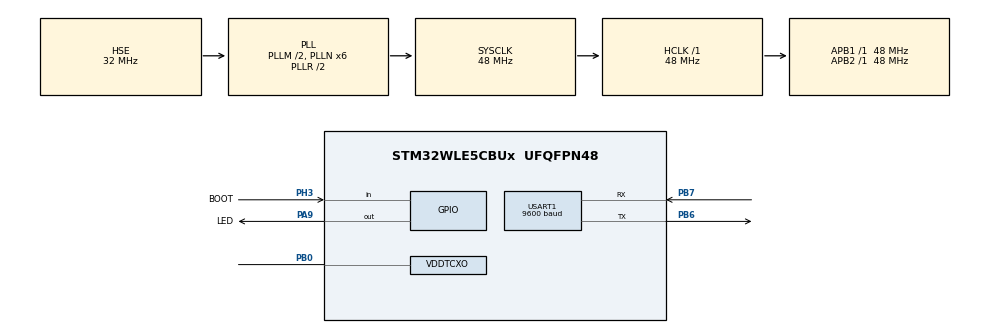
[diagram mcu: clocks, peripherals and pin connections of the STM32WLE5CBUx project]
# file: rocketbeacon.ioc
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ADC.NbrOfConversion=1
ADC.SelectedChannel=ADC_CHANNEL_VBAT
Dma.Request0=USART1_RX
Dma.USART1_RX.0.Direction=DMA_PERIPH_TO_MEMORY
Dma.USART1_RX.0.EventEnable=DISABLE
Dma.USART1_RX.0.Instance=DMA1_Channel1
Dma.USART1_RX.0.MemDataAlignment=DMA_MDATAALIGN_BYTE
Dma.USART1_RX.0.MemInc=DMA_MINC_ENABLE
Dma.USART1_RX.0.Mode=DMA_NORMAL
Dma.USART1_RX.0.PeriphDataAlignment=DMA_PDATAALIGN_BYTE
Dma.USART1_RX.0.PeriphInc=DMA_PINC_DISABLE
Dma.USART1_RX.0.Polarity=HAL_DMAMUX_REQ_GEN_RISING
Dma.USART1_RX.0.Priority=DMA_PRIORITY_MEDIUM
Dma.USART1_RX.0.RequestNumber=1
Dma.USART1_RX.0.SignalID=NONE
Dma.USART1_RX.0.SyncEnable=DISABLE
Dma.USART1_RX.0.SyncPolarity=HAL_DMAMUX_SYNC_NO_EVENT
Dma.USART1_RX.0.SyncRequestNumber=1
Dma.USART1_RX.0.SyncSignalID=NONE
Mcu.Family=STM32WL
Mcu.Name=STM32WLE5CBUx
Mcu.Package=UFQFPN48
NVIC.DMA1_Channel1_IRQn=true\:0\:0\:false\:false\:true\:false\:true\:true
NVIC.PriorityGroup=NVIC_PRIORITYGROUP_4
NVIC.USART1_IRQn=true\:0\:0\:false\:false\:true\:true\:true\:true
OSC_IN.Mode=HSE-TCXO
OSC_IN.Signal=RCC_OSC_IN
PA13.Mode=Serial_Wire
PA13.Signal=DEBUG_JTMS-SWDIO
PA14.Mode=Serial_Wire
PA14.Signal=DEBUG_JTCK-SWCLK
PA9.GPIO_Label=LED
PA9.Signal=GPIO_Output
PB0-VDD_TCXO.Mode=HSE-TCXO
PB0-VDD_TCXO.Signal=VDDTCXO
PB6.Mode=Asynchronous
PB6.Signal=USART1_TX
PB7.Mode=Asynchronous
PB7.Signal=USART1_RX
PH3-BOOT0.GPIO_Label=BOOT
PH3-BOOT0.Signal=GPIO_Input
ProjectManager.HeapSize=0x200
ProjectManager.StackSize=0x400
ProjectManager.TargetToolchain=STM32CubeIDE
RCC.AHB3CLKDivider=RCC_SYSCLK_DIV16
RCC.AHBFreq_Value=48000000
RCC.APB1Freq_Value=48000000
RCC.APB1TimFreq_Value=48000000
RCC.APB2Freq_Value=48000000
RCC.APB2TimFreq_Value=48000000
RCC.APB3Freq_Value=3000000
RCC.CortexFreq_Value=48000000
RCC.HCLKFreq_Value=48000000
RCC.HSE_VALUE=32000000
RCC.HSI_VALUE=16000000
RCC.LSE_VALUE=32768
RCC.PLLM=RCC_PLLM_DIV2
RCC.PLLN=6
RCC.PLLSourceVirtual=RCC_PLLSOURCE_HSE
RCC.SYSCLKFreq_VALUE=48000000
RCC.SYSCLKSource=RCC_SYSCLKSOURCE_PLLCLK
RCC.VCOOutputFreq_Value=96000000
USART1.BaudRate=9600
USART1.VirtualMode-Asynchronous=VM_ASYNC
VP_ADC_Vbat_Input.Mode=IN-Vbat
VP_CRC_VS_CRC.Mode=CRC_Activate
VP_SUBGHZ_VS_SUBGHZ.Mode=SUBGHZ_Activate
VP_TIM16_VS_ClockSourceINT.Mode=Enable_Timer
board=custom

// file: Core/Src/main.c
/* USER CODE BEGIN Header */
/**
  ******************************************************************************
  * @file           : main.c
  * @brief          : Main program body
  ******************************************************************************
  * @attention
  *
  * Copyright (c) 2024 STMicroelectronics.
  * All rights reserved.
  *
  * This software is licensed under terms that can be found in the LICENSE file
  * in the root directory of this software component.
  * If no LICENSE file comes with this software, it is provided AS-IS.
  *
  ******************************************************************************
  */
/* USER CODE END Header */
#include "main.h"
#include "adc.h"
#include "crc.h"
#include "dma.h"
#include "subghz.h"
#include "tim.h"
#include "usart.h"
#include "gpio.h"

void SystemClock_Config(void);

/* USER CODE BEGIN 0 */
void entrypoint(void);
/* USER CODE END 0 */

int main(void)
{

  /* MCU Configuration--------------------------------------------------------*/

  /* Reset of all peripherals, Initializes the Flash interface and the Systick. */
  HAL_Init();

  /* Configure the system clock */
  SystemClock_Config();

  /* Initialize all configured peripherals */
  MX_GPIO_Init();
  MX_DMA_Init();
  MX_ADC_Init();
  MX_SUBGHZ_Init();
  MX_CRC_Init();
  MX_USART1_UART_Init();
  MX_TIM16_Init();
  /* USER CODE BEGIN 2 */

  entrypoint();

  /* USER CODE END 2 */

  /* Infinite loop */
  while (1)
  {

  }
}

void SystemClock_Config(void)
{
  RCC_OscInitTypeDef RCC_OscInitStruct = {0};
  RCC_ClkInitTypeDef RCC_ClkInitStruct = {0};

  /** Configure the main internal regulator output voltage
  */
  __HAL_PWR_VOLTAGESCALING_CONFIG(PWR_REGULATOR_VOLTAGE_SCALE1);

  /** Initializes the CPU, AHB and APB buses clocks
  */
  RCC_OscInitStruct.OscillatorType = RCC_OSCILLATORTYPE_HSE;
  RCC_OscInitStruct.HSEState = RCC_HSE_BYPASS_PWR;
  RCC_OscInitStruct.HSEDiv = RCC_HSE_DIV1;
  RCC_OscInitStruct.PLL.PLLState = RCC_PLL_ON;
  RCC_OscInitStruct.PLL.PLLSource = RCC_PLLSOURCE_HSE;
  RCC_OscInitStruct.PLL.PLLM = RCC_PLLM_DIV2;
  RCC_OscInitStruct.PLL.PLLN = 6;
  RCC_OscInitStruct.PLL.PLLP = RCC_PLLP_DIV2;
  RCC_OscInitStruct.PLL.PLLR = RCC_PLLR_DIV2;
  RCC_OscInitStruct.PLL.PLLQ = RCC_PLLQ_DIV2;
  if (HAL_RCC_OscConfig(&RCC_OscInitStruct) != HAL_OK)
  {
    Error_Handler();
  }

  /** Configure the SYSCLKSource, HCLK, PCLK1 and PCLK2 clocks dividers
  */
  RCC_ClkInitStruct.ClockType = RCC_CLOCKTYPE_HCLK3|RCC_CLOCKTYPE_HCLK
                              |RCC_CLOCKTYPE_SYSCLK|RCC_CLOCKTYPE_PCLK1
                              |RCC_CLOCKTYPE_PCLK2;
  RCC_ClkInitStruct.SYSCLKSource = RCC_SYSCLKSOURCE_PLLCLK;
  RCC_ClkInitStruct.AHBCLKDivider = RCC_SYSCLK_DIV1;
  RCC_ClkInitStruct.APB1CLKDivider = RCC_HCLK_DIV1;
  RCC_ClkInitStruct.APB2CLKDivider = RCC_HCLK_DIV1;
  RCC_ClkInitStruct.AHBCLK3Divider = RCC_SYSCLK_DIV16;

  if (HAL_RCC_ClockConfig(&RCC_ClkInitStruct, FLASH_LATENCY_0) != HAL_OK)
  {
    Error_Handler();
  }
}

void Error_Handler(void)
{
  __disable_irq();
  while (1)
  {
  }
}
